# C7X256V_DEBUG_MATLOCK_REG_000734002000h register map
Vendor: Texas Instruments
Peripheral module from a debugger description file (folder am62D).
Registers are 32-bit, read-write, reset values left out (the file's numbers can be read two ways) unless marked. A register's access mark holds for its fields unless they carry their own. Offsets are as the file gives them; lines under a group give offsets from that group; [hi:lo] are bit positions; {n}, {i} and the like mark numbered series; 'fields as' and 'values as' point back to an identical list; <NAME> marks a mode.

## matlock_reg
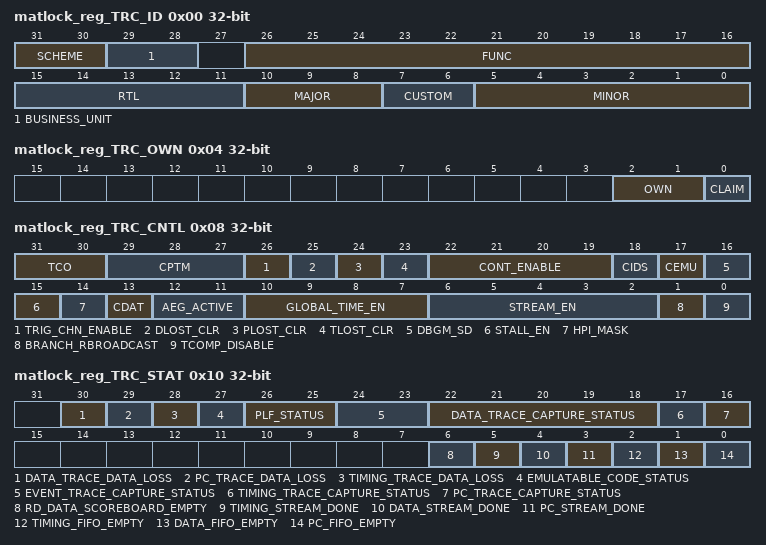
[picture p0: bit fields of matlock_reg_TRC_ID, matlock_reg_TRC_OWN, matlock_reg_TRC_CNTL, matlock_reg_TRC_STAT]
0x00 matlock_reg_TRC_ID access per field — Trace ID Register
  [31:30] SCHEME ro — Defines the scheme Reads return 01b
  [29:28] BUSINESS_UNIT ro — Business Unit Reads return 10b
  [26:16] FUNC ro — Functional Group 0x201 is reserved for C71 Trace Reads return 0x201
  [15:11] RTL ro — RTL Revision This value is implementation defined
  [10:8] MAJOR ro — Major Revision This is the first major revision of Trace Reads return 0x0
  [7:6] CUSTOM ro — Custom Field Reads return 0x0
  [5:0] MINOR ro — Minor Revision Reads return 0x0
0x04 matlock_reg_TRC_OWN access per field — Trace Ownership Control Register The Trace Ownership Control Register must be configured before any other trace subsystem resources can be programmed
  [2:1] OWN ro — The Ownership State
  [0] CLAIM rw — This bit is used to obtain exclusive ownership of the debug module for either the debug initiator or the application initiator Reads will always return 0 If the current state is NOT_OWNED o A debugger-initiated write of 1 will claim the module for use by the debugger initiator o An application-initiated write of 1 will claim the module for use by the application initiator If the current state is DBG_OWNED o A debugger-initiated write of 0 will release ownership o A debugger-initiated write of 1 has no effect o Application writes have no effect If the current state is APP_OWNED o An application-initiated write of 0 will release ownership o A debugger-initiated write of 0 will release ownership o A write of 1 has not effect
0x08 matlock_reg_TRC_CNTL — Trace Control Register
  [31:30] TCO — Last Stall Standing Timing Compression Scheme
  [29:27] CPTM — Event Profiling Trace Mode These bits identify the mode in which trace is operating When an event profiling mode is configured this is equivalent to an enable to allow the data trace stream to be used for collection of event trace only Event trace is only collected in following cases though: In PEP mode: PC trace stream is enabled and AET PC trigger is currently allowing PC sample capture When one or more of the conditions is not met from being met then any partially buffered event trace messages are exported In AEP mode: Timing and PC trace streams are enabled and AET PC and Timing triggers are currently allowing PC sample capture When one or more of the conditions is not met from being met then any partially buffered event trace messages are exported In EEP mode: Timing trace stream is enabled and AET Timing trigger is currently allowing Timing sample capture When one or more of the conditions is not met from being met then any partially buffered event trace messages are exported In LSS mode: Same as for AEP mode When an event mode is configured, AET triggers pertaining to storing the data value part of memory transactions shall be ignored
  [26] TRIG_CHN_ENABLE — Trigger Channel Enable Enable chaining of the two applicaiton control and status registers to support an atomic 64-bit write access
  [25] DLOST_CLR — Clear the Data Trace Loss Sticky Status Bit
  [24] PLOST_CLR — Clear the PC Trace Loss Sticky Status Bit
  [23] TLOST_CLR — Clear the Timing Trace Loss Sticky Status Bit
  [22:19] CONT_ENABLE — Context Enable These bits should be changed when the PC and Data trace streams are both disabled Changing these bits when PC and/or Data Trace stream is enabled shall be ignored
  [18] CIDS — Continue during Interrupt During Suspend Allows recordign of activity related ot the servicing of an HPI while the CPU execution has been suspended by any type of debug action This bit should be changed prior to PC, Data, and Timing treams being enabled Changes after this may be ignored by hardware
  [17] CEMU — Continue during Debug Activity Allows the recording of stalls due to debug activity while the CPU execution has been suspended by any type of debug action or when CIDS=0 and foreground code execution is active This bit should be changed prior to the timing stream being enabled Changes made while the timing stream is enabled may be ignored by the hardware
  [16] DBGM_SD — DBGM Stall Disable
  [15] STALL_EN — CPU Stall Enable Controls the action taken when additional data from the CPU will cause buffers to lose data as the trace internal FIFO is full If set, the CPU will be stalled unless the DBGM bit is set or the application is currently in a HPI
  [14] HPI_MASK — HPI Mask This bti allows stalling the CPU while processing a high priority interrupt if the FIFO is getting full and STALL_EN bit is set
  [13] CDAT — CDAT Allows the recording of activity in the data trace stream either due to debug memory accesses being generated or due to an event trace mode such as EEP mode generating trace activity that is required to be collected in the data trace stream while the CPU execution has been suspended by any type of debug action or when CIDS=0 and foreground code execution is active This bit should be changed prior to the data stream or event trace mode being enabled Changes made whilst data stream is enabled [or an event trace mode is enabled] may be ignored by the hardware
  [12:11] AEG_ACTIVE — AEG_ACTIVE This bit reflects the total number of AEG events that are active for trace
  [10:7] GLOBAL_TIME_EN — Global Timestamp Enable These enables allow insertion of the global timestamps into trace streams below These bits should be set or cleared before the corresponding stream enables have been set Changing the values after the corresponding stream is enabled shall be ignored
  [6:2] STREAM_EN — Trace Stream Enables When an enable bit transitions from 0->1 all FIFO's and scoreboards associated with that stream are reset When an enable bit transitions from 1-> the stream may not be immediately disabled if scoreboards or partial trace packets have to be flushed but the bit4 shall change state immediately
  [1] BRANCH_RBROADCAST — Branch Broadcast This bit can be set to enable branch broadcasting mode This bit should be set or cleared before the PC trace stream is enabled Any changes made after the PC trace stream is enabled shall be ignored When branch broadcasting is enabled, PC offset compression is disabled for address parameters of branch and exception command packets and sign extended compression is enabled
  [0] TCOMP_DISABLE — Timing Stream Compression Disable This bit can be set to disable the timing stream compression This bit shoudl only be set or cleared when the instruction advance timing stream is disabled Any attempts to change this bit while the timing stream is enabled shall result in writes to this bit being ignored
0x0C matlock_reg_TRC_PER_CNT — Trace Periodic Counter Register The periodic counter register specifies a count of the total number of bytes transmitted on the ATB interface after which a periodic sync point is generated in the streams that are active. This register is also used to periodically generate alignment synchronization sequences.
  [15:0] COUNTER — Synchronization Frequency A value of 0 disables the counter A reset sets the frequence by default to '1024'
0x10 matlock_reg_TRC_STAT access per field — Trace Status Register This register is used to establish whether the Matlock Encode Hardware is no longer queuing trace packets in the respective trace streams and also the status of the respective trace queues (whether empty or not). It can also be used to determine if trace capture is currently active or not for any of the trace queues. When a trace stream is being disabled from the enabled state, due to a trigger or ownership loss or disabling the enable bit for the trace stream or clearing the enable bit in export control register, any partially built trace packets must be drained into the respective trace queue. When the partially built trace packets have been drained then the respective done bits shall be set. The respective FIFO empty bits shall only be set when all trace data has been passed from Matlock Encode Hardware to the Matlock Export Block. The statuses available in this register are for debug purposes only and not required in any programming model.
  [30] DATA_TRACE_DATA_LOSS ro — Set to one by a data trace gap packet being generated Reset by Writing a 1 to TRC_CNTL:DLOST_CLR or when all data trace related streams are disabled [ie memory read, write, streaming buffer and event trace] and then one or more of them are re-enabled indicating a new trace session A loss of ownership also causes this status bit to be reset A simultaneous set and reset causes the bit to be set
  [29] PC_TRACE_DATA_LOSS ro — Set to one by a PC trace gap packet being generated Reset by Writing a 1 to TRC_CNTL:PLOST_CLR or a zero to one transition on TRC_CNTL:STREAM_EN [PC Trace] or a loss of ownership A simultaneous set and reset causes the bit to be set
  [28] TIMING_TRACE_DATA_LOSS ro — Set to one by a timing trace gap packet being generated Reset by Writing a 1 to TRC_CNTL:TLOST_CLR or a zero to one transition on TRC_CNTL:STREAM_EN [Timing Trace] or a loss of ownership A simultaneous set and reset causes the bit to be set
  [27] EMULATABLE_CODE_STATUS ro — The status of whether we are in untraceable secure code or not
  [26:25] PLF_STATUS ro — The pipeline flattener status
  [24:23] EVENT_TRACE_CAPTURE_STATUS ro — These bits indicate whether any data is being captured for a particular event trace mode This status accounts for all conditions [ie triggers, CPU states, trace enables and security] required to ascertain whether event trace can be collected or not
  [22:18] DATA_TRACE_CAPTURE_STATUS ro — This status accounts for triggers, stream enables, enable bit in Trace Export Control Register and PLF conditions and security Bit 22 Streaming Buffer Bit 21 Read Data Bit 20 Read Address Bit 19 Write Data Bit 18 Write Address
  [17] TIMING_TRACE_CAPTURE_STATUS ro — This status accounts for triggers, stream enables, enable bit in the trace export control register and PLF conditions and security
  [16] PC_TRACE_CAPTURE_STATUS ro — This status accounts for triggers, stream enables, enable bit in the trace export control register and PLF conditions and security
  [6] RD_DATA_SCOREBOARD_EMPTY ro
  [5] TIMING_STREAM_DONE ro
  [4] DATA_STREAM_DONE ro
  [3] PC_STREAM_DONE ro
  [2] TIMING_FIFO_EMPTY ro
  [1] DATA_FIFO_EMPTY ro
  [0] PC_FIFO_EMPTY ro
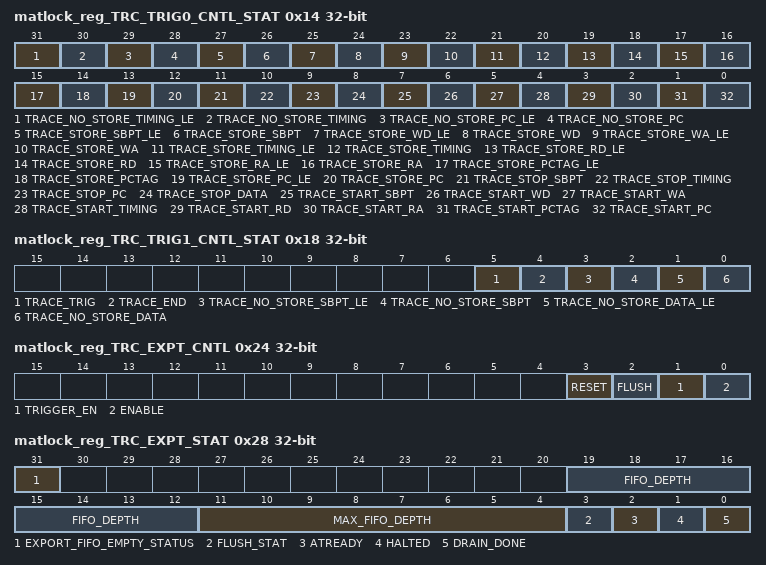
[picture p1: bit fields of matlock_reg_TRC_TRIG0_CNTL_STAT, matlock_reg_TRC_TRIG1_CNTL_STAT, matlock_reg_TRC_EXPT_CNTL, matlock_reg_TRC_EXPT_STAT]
0x14 matlock_reg_TRC_TRIG0_CNTL_STAT — Trace Trigger Control and Status Register The trace trigger control and status registers may be used to enable or disable trace data capture in the PC, Timing or Data Trace Streams without touching the AET module. The trigger registers may also be used in conjunction with AET to provide additional resources for trigger generation. When trigger register chaining mode is enabled in the trace ctrl register, software must follow this sequence: Write to TRC_TRIG0_CNTL_STAT register which does not immediately take effect Write to TRC_TRIG1_CNTL_STAT register which results in a 64-bit write taking effect to include the last update to TRC_TRIG1_CNTL_STAT register. The status bits in both of the trigger control and status registers when indicating that a trace capture window is not active do not account for effects such as: Flushing partial branch bits packets PRELIMINARY documents contain information on a product under development and are issued for evaluation purposes only. Features, characteristic data and other information are subject to change. TI Confidential NDA Restrictions UNDER NON DISCLOSURE AGREEMENT. DO NOT COPY. Page 171 of 188 Flushing read data scoreboard Flushing partial timing packets Flushing partial event trace packets Generating Sync Points that are required due to one or more trace streams being disabled The status bit only indicates that a trace capture window is being disabled. The status bits account for all parameters required to decide if a capture window is open or not: AET triggers Application triggers Security PLF conditions (i.e. foreground or background code execution or halted status) Trace Stream Enables Trace Enable bit in the Trace Export Control Register
  [31] TRACE_NO_STORE_TIMING_LE — Load Enable for TRACE_NO_STORE_TIMING Write 1: Allows TRACE_NO_STORE_TIMING field to be updated with the value presented to that field Write 0: No effect
  [30] TRACE_NO_STORE_TIMING — Write 0/1: This bit updates level of TRACE_NO_STORE_Timing trigger when the next higher bit is set Read 0: Timing trace capture window is active for Timing trace stream Read 1: Timing trace capture is not active or is being disabled for the Timing trace stream
  [29] TRACE_NO_STORE_PC_LE — Load Enable for TRACE_NO_STORE_PC Write 1: Allows TRACE_NO_STORE_PC field to be updated with the value presented to that field Write 0: No effect
  [28] TRACE_NO_STORE_PC — Write 0/1: This bit updates level of TRACE_NO_STORE_PC trigger when the next higher bit is set Read 0: PC trace capture window is active for PC trace stream Read 1: PC trace capture is not active or is being disabled for the PC trace stream
  [27] TRACE_STORE_SBPT_LE — Load Enable for TRACE_STORE_SBPT Write 1: Allows TRACE_STORE_SBPT field to be updated with the value presented to that field Write 0: No effect
  [26] TRACE_STORE_SBPT — Write 0/1: This bit updates level of TRACE_STORE_SBPT trigger when the next higher bit is set Read 0: SBPT capture window is not active or is being disabled for data trace stream Read 1: SBPT capture window is active for the data trace stream
  [25] TRACE_STORE_WD_LE — Load Enable for TRACE_STORE_WD Write 1: Allows TRACE_STORE_WD field to be updated with the value presented to that field Write 0: No effect
  [24] TRACE_STORE_WD — Write 0/1: This bit updates level of TRACE_STORE_WD trigger when the next higher bit is set Read 0: WD capture window is not active or is being disabled for data trace stream Read 1: WD capture window is active for the data trace stream
  [23] TRACE_STORE_WA_LE — Load Enable for TRACE_STORE_WA Write 1: Allows TRACE_STORE_WA field to be updated with the value presented to that field Write 0: No effect
  [22] TRACE_STORE_WA — Write 0/1: This bit updates level of TRACE_STORE_WA trigger when the next higher bit is set Read 0: WA capture window is not active or is being disabled for data trace stream Read 1: WA capture window is active for the data trace stream
  [21] TRACE_STORE_TIMING_LE — Load Enable for TRACE_STORE_TIMING Write 1: Allows TRACE_STORE_TIMING field to be updated with the value presented to that field Write 0: No effect
  [20] TRACE_STORE_TIMING — Write 0/1: This bit updates level of TRACE_STORE_TIMING trigger when the next higher bit is set Read 0: Timing capture window is not active or is being disabled for data trace stream Read 1: Timing capture window is active for the data trace stream
  [19] TRACE_STORE_RD_LE — Load Enable for TRACE_STORE_RD Write 1: Allows TRACE_STORE_RD field to be updated with the value presented to that field Write 0: No effect
  [18] TRACE_STORE_RD — Write 0/1: This bit updates level of TRACE_STORE_RD trigger when the next higher bit is set Read 0: RD capture window is not active or is being disabled for data trace stream Read 1: RD capture window is active for the data trace stream
  [17] TRACE_STORE_RA_LE — Load Enable for TRACE_STORE_RA Write 1: Allows TRACE_STORE_RA field to be updated with the value presented to that field Write 0: No effect
  [16] TRACE_STORE_RA — Write 0/1: This bit updates level of TRACE_STORE_RA trigger when the next higher bit is set Read 0: RA capture window is not active or is being disabled for data trace stream Read 1: RA capture window is active for the data trace stream
  [15] TRACE_STORE_PCTAG_LE — Load Enable for TRACE_STORE_PCTAG Write 1: Allows TRACE_STORE_PCTAG field to be updated with the value presented to that field Write 0: No effect
  [14] TRACE_STORE_PCTAG — Write 0/1: This bit updates level of TRACE_STORE_PCTAG trigger when the next higher bit is set Read 0: PCTAG attributes are not being collected or are being disabled for data trace stream Read 1: PCTAG attributes are being collected for the data trace stream
  [13] TRACE_STORE_PC_LE — Load Enable for TRACE_STORE_PC Write 1: Allows TRACE_STORE_PC field to be updated with the value presented to that field Write 0: No effect
  [12] TRACE_STORE_PC — Write 0/1: This bit updates level of TRACE_STORE_PC trigger when the next higher bit is set Read 0: PC capture window is not active or is being disabled Read 1: PC capture window is active
  [11] TRACE_STOP_SBPT — Write 1: This bit when set shall generate a pulse on the TRACE_STOP_SBPT trigger Write 0: No effect Read 0: SBPT capture window is not active or is being disabled Read 1: SBPT capture window is active
  [10] TRACE_STOP_TIMING — Write 1: This bit when set shall generate a pulse on the TRACE_STOP_TIMING trigger Write 0: No effect Read 0: Timing trace stream capture window is not active or is being disabled Read 1: Timing trace stream capture window is active
  [9] TRACE_STOP_PC — Write 1: This bit when set shall generate a pulse on the TRACE_STOP_PC trigger Write 0: No effect Read 0: PC trace stream capture window is not active or is being disabled Read 1: PC trace stream capture window is active
  [8] TRACE_STOP_DATA — Write 1: This bit when set shall generate a pulse on the TRACE_STOP_DATA trigger Write 0: No effect Read 0: Data trace stream window is not active for either of PCTAG, WA, WD, RA, RD or is being disabled Read 1: Data trace stream window is active for any of PCTAG, WA, WD, RA, RD
  [7] TRACE_START_SBPT — Write 1: This bit when set shall generate a pulse on the TRACE_START_SBPT trigger Write 0: No effect Read 0: Data trace stream SBPT window is not active or is being disabled Read 1: Data trace stream SBPT window is active
  [6] TRACE_START_WD — Write 1: This bit when set shall generate a pulse on the TRACE_START_WD trigger Write 0: No effect Read 0: Data trace stream WD window is not active or is being disabled Read 1: Data trace stream WD window is active
  [5] TRACE_START_WA — Write 1: This bit when set shall generate a pulse on the TRACE_START_WA trigger Write 0: No effect Read 0: Data trace stream WA window is not active or is being disabled Read 1: Data trace stream WA window is active
  [4] TRACE_START_TIMING — Write 1: This bit when set shall generate a pulse on the TRACE_START_TIMING trigger Write 0: No effect Read 0: Timing trace window is not active or is being disabled Read 1: Timing trace window is active
  [3] TRACE_START_RD — Write 1: This bit when set shall generate a pulse on the TRACE_START_RD trigger Write 0: No effect Read 0: Data Stream RD trace window is not active or is being disabled Read 1: Data Stream RD trace window is active
  [2] TRACE_START_RA — Write 1: This bit when set shall generate a pulse on the TRACE_START_RA trigger Write 0: No effect Read 0: Data Stream RA trace window is not active or is being disabled Read 1: Data Strea
  [1] TRACE_START_PCTAG — Write 1: This bit when set shall generate a pulse on the TRACE_START_PCTAG trigger Write 0: No effect Read 0: PCTAG attribute collection is not active or is being disabled Read 1: PCTAG attribute collection is active
  [0] TRACE_START_PC — Write 1: This bit when set shall generate a pulse on the TRACE_START_PC trigger Write 0: No effect Read 0: PC trace window is not active or is being disabled Read 1: PC trace window is active
0x18 matlock_reg_TRC_TRIG1_CNTL_STAT — Trace Trigger Control and Status Register The trace trigger control and status registers may be used to enable or disable trace data capture in the PC, Timing or Data Trace Streams without touching the AET module. The trigger registers may also be used in conjunction with AET to provide additional resources for trigger generation. When trigger register chaining mode is enabled in the trace ctrl register, software must follow this sequence: Write to TRC_TRIG0_CNTL_STAT register which does not immediately take effect Write to TRC_TRIG1_CNTL_STAT register which results in a 64-bit write taking effect to include the last update to TRC_TRIG1_CNTL_STAT register. The status bits in both of the trigger control and status registers when indicating that a trace capture window is not active do not account for effects such as: Flushing partial branch bits packets PRELIMINARY documents contain information on a product under development and are issued for evaluation purposes only. Features, characteristic data and other information are subject to change. TI Confidential NDA Restrictions UNDER NON DISCLOSURE AGREEMENT. DO NOT COPY. Page 171 of 188 Flushing read data scoreboard Flushing partial timing packets Flushing partial event trace packets Generating Sync Points that are required due to one or more trace streams being disabled The status bit only indicates that a trace capture window is being disabled. The status bits account for all parameters required to decide if a capture window is open or not: AET triggers Application triggers Security PLF conditions (i.e. foreground or background code execution or halted status) Trace Stream Enables Trace Enable bit in the Trace Export Control Register
  [5] TRACE_TRIG — Write 1: This bit shall generate a pulse on Trace Trigger Write 0 : No effect
  [4] TRACE_END — Write 1: This bit shall generate a pulse on Trace End Trigger Write 0 : No effect
  [3] TRACE_NO_STORE_SBPT_LE — Load Enable for TRACE_NO_STORE_SBPT Write 1: Allows TRACE_NO_STORE_SBPT field to be updated with the value presented to that field Write 0: No effect
  [2] TRACE_NO_STORE_SBPT — Write 0/1: This bit updates level of TRACE_NO_STORE_SBPT trigger when the next higher bit is set Read 0: SPBT trace capture window is active for data trace stream Read 1: SPBT trace capture is not active for the data trace stream or is being disabled
  [1] TRACE_NO_STORE_DATA_LE — Load Enable for TRACE_NO_STORE_DATA Write 1: Allows TRACE_NO_STORE_DATA field to be updated with the value presented to that field Write 0: No effect
  [0] TRACE_NO_STORE_DATA — Write 0/1: This bit updates level of TRACE_NO_STORE_DATA trigger when the next higher bit is set Read 0: Data trace capture window is active for either of RA,WA,RD,WD Read 1: Data trace capture window is not active for any of RA,WA,RD,WD or is being disabled
0x1C matlock_reg_TRC_TIMESTAMP_CNT_REG0 — This register returns the least significant 32-bits of the 48-bit external global timestamp counter. When this register is read the upper 16-bits of the global timestamp are loaded into a shadow register which may be read when the Trace TimeStamp Counter Register 1 is read. The shadow register is only ever updated when the Trace Time Stamp Counter Register 0 is read.
  [31:0] GLOBAL_TIMESTAMP — Least Significant 32-bits of the external global timestamp
0x20 matlock_reg_TRC_TIMESTAMP_CNT_REG1 — This register returns the most significant 16-bits of the external global timestamp counter loaded from a shadow register. The shadow register is updated every time the Trace Time Stamp Counter Register 0 is read. The value read from this register may be stale (or undefined) if software does not first read the Trace Time Stamp Counter Register 0.
  [15:0] GLOBAL_TIMESTAMP — Bits 47:32 of the external global timestamp read from a shadow register which captures the most significant 16-bits of the global timestamp when the bottom 32-bits are read
0x24 matlock_reg_TRC_EXPT_CNTL
  [3] RESET — Writing a 1 to this bit will initiate a reset of read and write synchronous FIFO pointers and will disable the export module by clearing all writable bits in this register and updating the Trace Export Status register bits to their reset state The bit will reset automatically to a 0 after the reset has been completed and will read as 1 whilst the reset is ongoing
  [2] FLUSH — Writing a 1 to this bit will initiate an internal trace flush This bit reads as 1 until the initiated flush is completed
  [1] TRIGGER_EN — Writing a 1 to this bit shall enable embedded triggers to be inserted into the ATB data stream
  [0] ENABLE — When written with a 1, this is a request to enable trace export and acquisition from the PLF interface When written with a 0, this is a request to disable trace export This also requests disablement of collection of new trace data from the PLF interface since it cannot be exported This is equivalent of clearing AET triggers and not allowing collection of trace data When read as a 1, this means trace export has been requested to be enabled or is enabled When read as a 0, this means trace export has been requested to be disabled or is disabled Trace Export may be confirmed as disabled by waiting for the HALTED bit to go from 0->1 The Trace FIFO is confirmed as empty when the DRAIN_DONE bit is set
0x28 matlock_reg_TRC_EXPT_STAT access per field
  [31] EXPORT_FIFO_EMPTY_STATUS ro — Read 0: Export FIFO is not empty Read 1: Export FIFO is empty This is a status for the Export FIFO When this bit is set it does not indicate the state of other storage elements inside Matlocks acquisition logic This status is to be used for debug purposes only The drain_done bit is the master status for all storage elements inside Matlock
  [19:12] FIFO_DEPTH ro — Set to the FIFO depth of the synchronous FIFO in export module in terms of entries as implemented in this module by the designer
  [11:4] MAX_FIFO_DEPTH ro — This is a field when read indicates the current max depth of export FIFO utilization in terms of FIFO entries 0 indicates FIFO empty The field is updated when trace export is enabled and may be read at any time Reading of the field may indicate FIFO full conditions by comparing the value to the known FIFO depth set at compile time
  [3] FLUSH_STAT ro
  [2] ATREADY ro
  [1] HALTED ro
  [0] DRAIN_DONE ro
0x2C matlock_reg_TRC_EXPT_ATID — Trace Export Trace ID Register
  [3:0] ATID — The ATID to output with valid trace data on the ATB interface
